# PIC32CM1216JH01032 device description
Architecture: CORTEX-M0PLUS; Family: PIC32CM; Series: PIC32CMJH01
Registers are 32-bit, read-write, reset 0x0 unless marked. A register's access mark holds for its fields unless they carry their own. Offsets are from the block's base; [hi:lo] are bit positions; {n}, {i} and the like mark numbered series.

## SMBIST — SRAM MBIST Interface
Instances: SMBIST 0x42006c00
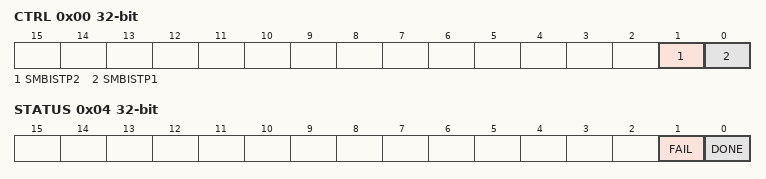
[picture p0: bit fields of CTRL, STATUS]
0x00 CTRL — Control
  [1] SMBISTP2 — SRAM MBIST Partition 2 test start
  [0] SMBISTP1 — SRAM MBIST Partition 1 test start
0x04 STATUS
  [1] FAIL, [0] DONE

## MCLK — Main Clock
Instances: MCLK 0x40000800
0x01 INTENCLR 8-bit (atomic clear) — Interrupt Enable Clear
  [0] CKRDY — Clock Ready Interrupt Enable
0x02 INTENSET 8-bit (atomic set) — Interrupt Enable Set
  [0] CKRDY — Clock Ready Interrupt Enable
0x03 INTFLAG 8-bit reset 0x1 (atomic clear) — Interrupt Flag Status and Clear
  [0] CKRDY — Clock Ready
0x04 CPUDIV 8-bit reset 0x1 — CPU Clock Division
  [7:0] CPUDIV — CPU Clock Division Factor
    1=DIV1 (Divide by 1); 2=DIV2 (Divide by 2); 4=DIV4 (Divide by 4); 8=DIV8 (Divide by 8); 16=DIV16 (Divide by 16); 32=DIV32 (Divide by 32); 64=DIV64 (Divide by 64); 128=DIV128 (Divide by 128)
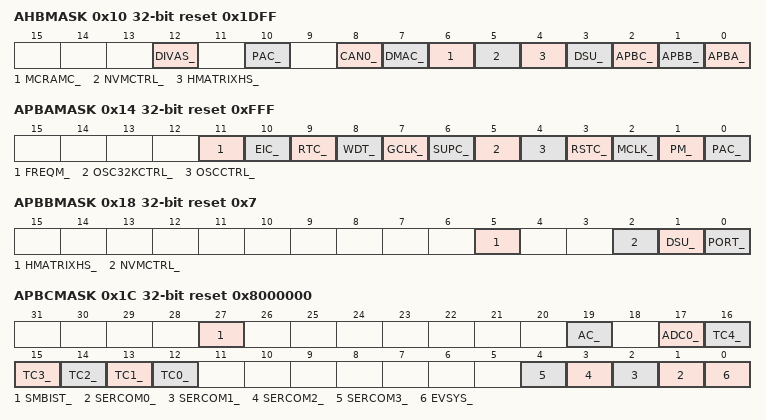
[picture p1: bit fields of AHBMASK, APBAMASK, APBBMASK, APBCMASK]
0x10 AHBMASK reset 0x1DFF
  [12] DIVAS_ — DIVAS AHB Clock Mask
  [10] PAC_ — PAC AHB Clock Mask
  [8] CAN0_ — CAN0 AHB Clock Mask
  [7] DMAC_ — DMAC AHB Clock Mask
  [6] MCRAMC_ — SRAM AHB Clock Mask
  [5] NVMCTRL_ — NVMCTRL AHB Clock Mask
  [4] HMATRIXHS_ — HMATRIXHS AHB Clock Mask
  [3] DSU_ — DSU AHB Clock Mask
  [2] APBC_ — APBC AHB Clock Mask
  [1] APBB_ — APBB AHB Clock Mask
  [0] APBA_ — APBA AHB Clock Mask
0x14 APBAMASK reset 0xFFF
  [11] FREQM_ — FREQM APB Clock Enable
  [10] EIC_ — EIC APB Clock Enable
  [9] RTC_ — RTC APB Clock Enable
  [8] WDT_ — WDT APB Clock Enable
  [7] GCLK_ — GCLK APB Clock Enable
  [6] SUPC_ — SUPC APB Clock Enable
  [5] OSC32KCTRL_ — OSC32KCTRL APB Clock Enable
  [4] OSCCTRL_ — OSCCTRL APB Clock Enable
  [3] RSTC_ — RSTC APB Clock Enable
  [2] MCLK_ — MCLK APB Clock Enable
  [1] PM_ — PM APB Clock Enable
  [0] PAC_ — PAC APB Clock Enable
0x18 APBBMASK reset 0x7
  [5] HMATRIXHS_ — HMATRIXHS APB Clock Enable
  [2] NVMCTRL_ — NVMCTRL APB Clock Enable
  [1] DSU_ — DSU APB Clock Enable
  [0] PORT_ — PORT APB Clock Enable
0x1C APBCMASK reset 0x8000000
  [27] SMBIST_ — SMBIST APB Clock Enable
  [19] AC_ — AC APB Clock Enable
  [17] ADC0_ — ADC0 APB Clock Enable
  [n+12] TC{n}_ (n=0..4) — TC{n} APB Clock Enable
  [n+1] SERCOM{n}_ (n=0..3) — SERCOM{n} APB Clock Enable
  [0] EVSYS_ — EVSYS APB Clock Enable

## MPU — Memory Protection Unit
Instances: MPU 0xE000ED90
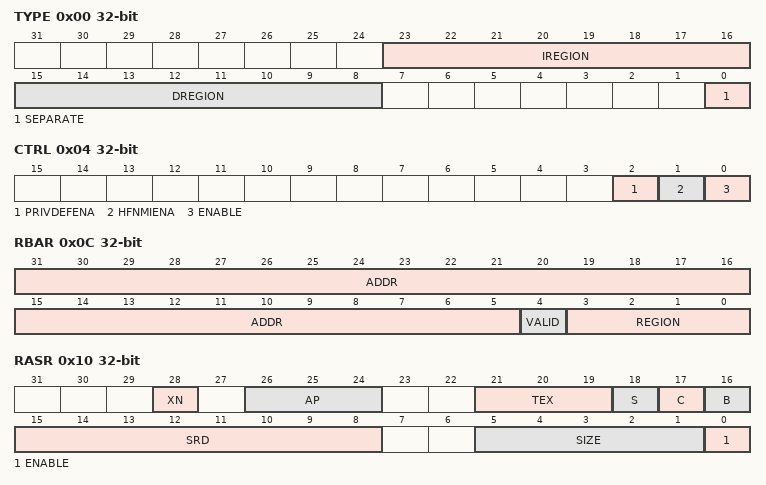
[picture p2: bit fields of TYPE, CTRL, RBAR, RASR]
0x00 TYPE ro reset not defined — MPU Type Register
  [23:16] IREGION — Number of Instruction Regions
  [15:8] DREGION — Number of Data Regions
  [0] SEPARATE — Separate instruction and Data Memory MapsRegions
0x04 CTRL reset not defined — MPU Control Register
  [2] PRIVDEFENA — Enables privileged software access to default memory map
  [1] HFNMIENA — Enable Hard Fault and NMI handlers
  [0] ENABLE — MPU Enable
0x08 RNR reset not defined — MPU Region Number Register
  [7:0] REGION — Region referenced by RBAR and RASR
0x0C RBAR reset not defined — MPU Region Base Address Register
  [31:5] ADDR — Region base address
  [4] VALID — Region number valid
  [3:0] REGION — Region number
0x10 RASR reset not defined — MPU Region Attribute and Size Register
  [28] XN — Execute Never Attribute
  [26:24] AP — Access Permission
  [21:19] TEX — TEX bit
  [18] S — Shareable bit
  [17] C — Cacheable bit
  [16] B — Bufferable bit
  [15:8] SRD — Sub-region disable
  [5:1] SIZE — Region Size
  [0] ENABLE — Region Enable

## MTB — Cortex-M0+ Micro-Trace Buffer
Instances: MTB 0x41008000
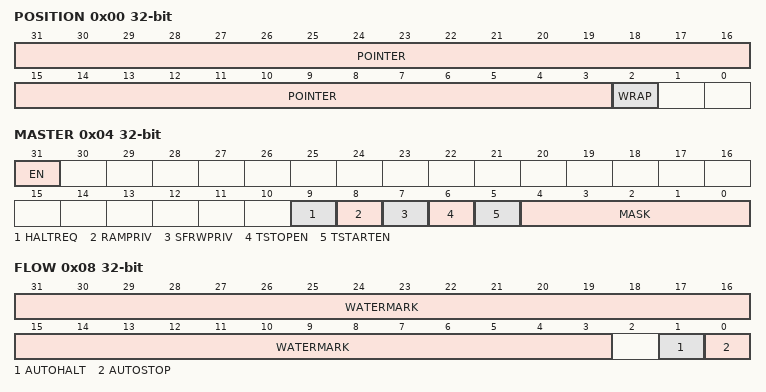
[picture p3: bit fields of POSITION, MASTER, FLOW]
0x00 POSITION reset not defined — MTB Position
  [31:3] POINTER — Trace Packet Location Pointer
  [2] WRAP — Pointer Value Wraps
0x04 MASTER — MTB Master
  [31] EN — Main Trace Enable
  [9] HALTREQ — Halt Request
  [8] RAMPRIV — SRAM Privilege
  [7] SFRWPRIV — Special Function Register Write Privilege
  [6] TSTOPEN — Trace Stop Input Enable
  [5] TSTARTEN — Trace Start Input Enable
  [4:0] MASK — Maximum Value of the Trace Buffer in SRAM
0x08 FLOW — MTB Flow
  [31:3] WATERMARK — Watermark value
  [1] AUTOHALT — Auto Halt Request
  [0] AUTOSTOP — Auto Stop Tracing
0x0C BASE ro reset not defined — MTB Base
0xF00 ITCTRL reset not defined — MTB Integration Mode Control
0xFA0 CLAIMSET reset not defined (atomic set) — MTB Claim Set
0xFA4 CLAIMCLR reset not defined (atomic clear) — MTB Claim Clear
0xFB0 LOCKACCESS reset not defined — MTB Lock Access
0xFB4 LOCKSTATUS ro reset not defined — MTB Lock Status
0xFB8 AUTHSTATUS ro reset not defined — MTB Authentication Status
0xFBC DEVARCH ro reset not defined — MTB Device Architecture
0xFC8 DEVID ro reset not defined — MTB Device Configuration
0xFCC DEVTYPE ro reset not defined — MTB Device Type
{0xFC0+4i} PID{i} ro reset not defined (i=4..7) — Peripheral Identification {i}
{0xFE0+4i} PID{i} ro reset not defined (i=0..3) — Peripheral Identification {i}
{0xFF0+4i} CID{i} ro reset not defined (i=0..3) — Component Identification {i}
